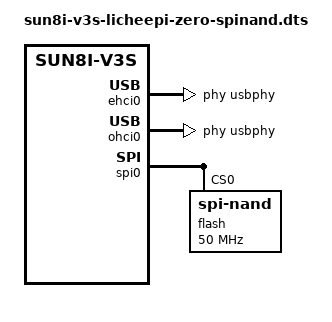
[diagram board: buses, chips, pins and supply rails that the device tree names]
/*
 * Copyright (C) 2019 Benedikt-Alexander Mokroß <bam@icognize.de>
 *
 * This file is dual-licensed: you can use it either under the terms
 * of the GPL or the X11 license, at your option. Note that this dual
 * licensing only applies to this file, and not this project as a
 * whole.
 *
 *  a) This file is free software; you can redistribute it and/or
 *     modify it under the terms of the GNU General Public License as
 *     published by the Free Software Foundation; either version 2 of the
 *     License, or (at your option) any later version.
 *
 *     This file is distributed in the hope that it will be useful,
 *     but WITHOUT ANY WARRANTY; without even the implied warranty of
 *     MERCHANTABILITY or FITNESS FOR A PARTICULAR PURPOSE.  See the
 *     GNU General Public License for more details.
 *
 * Or, alternatively,
 *
 *  b) Permission is hereby granted, free of charge, to any person
 *     obtaining a copy of this software and associated documentation
 *     files (the "Software"), to deal in the Software without
 *     restriction, including without limitation the rights to use,
 *     copy, modify, merge, publish, distribute, sublicense, and/or
 *     sell copies of the Software, and to permit persons to whom the
 *     Software is furnished to do so, subject to the following
 *     conditions:
 *
 *     The above copyright notice and this permission notice shall be
 *     included in all copies or substantial portions of the Software.
 *
 *     THE SOFTWARE IS PROVIDED "AS IS", WITHOUT WARRANTY OF ANY KIND,
 *     EXPRESS OR IMPLIED, INCLUDING BUT NOT LIMITED TO THE WARRANTIES
 *     OF MERCHANTABILITY, FITNESS FOR A PARTICULAR PURPOSE AND
 *     NONINFRINGEMENT. IN NO EVENT SHALL THE AUTHORS OR COPYRIGHT
 *     HOLDERS BE LIABLE FOR ANY CLAIM, DAMAGES OR OTHER LIABILITY,
 *     WHETHER IN AN ACTION OF CONTRACT, TORT OR OTHERWISE, ARISING
 *     FROM, OUT OF OR IN CONNECTION WITH THE SOFTWARE OR THE USE OR
 *     OTHER DEALINGS IN THE SOFTWARE.
 */

/dts-v1/;
#include "sun8i-v3s-licheepi-zero.dts"

/ {
	soc {
		ehci0: usb@01c1a000 {
			compatible = "allwinner,sun8i-v3s-ehci", "generic-ehci";
			reg = <0x01c1a000 0x100>;
			interrupts = <GIC_SPI 72 IRQ_TYPE_LEVEL_HIGH>;
			clocks = <&ccu CLK_BUS_EHCI0>, <&ccu CLK_BUS_OHCI0>;
			resets = <&ccu RST_BUS_EHCI0>, <&ccu RST_BUS_OHCI0>;
			phys = <&usbphy 0>;
			phy-names = "usb";
			status = "okay";
		};

		ohci0: usb@01c1a400 {
			compatible = "allwinner,sun8i-v3s-ohci", "generic-ohci";
			reg = <0x01c1a400 0x100>;
			interrupts = <GIC_SPI 73 IRQ_TYPE_LEVEL_HIGH>;
			clocks = <&ccu CLK_BUS_EHCI0>, <&ccu CLK_BUS_OHCI0>, <&ccu CLK_USB_OHCI0>;
			resets = <&ccu RST_BUS_EHCI0>, <&ccu RST_BUS_OHCI0>;
			phys = <&usbphy 0>;
			phy-names = "usb";
			status = "okay";
		};
	};
};

&spi0 {
	pinctrl-names = "default";
	pinctrl-0 = <&spi0_pins>;
	status = "okay";

	flash: spinand@0 {
		#address-cells = <1>;
		#size-cells = <1>;
		compatible = "spi-nand";
		reg = <0>;
		spi-max-frequency = <50000000>;

		boot@0 {
			label = "boot";
			reg = <0x0000000 0x0100000>;
		};

		ubi0@100000 {
			label = "ubi0";
			reg = <0x0100000 0x0000000>;
		};

	};
};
